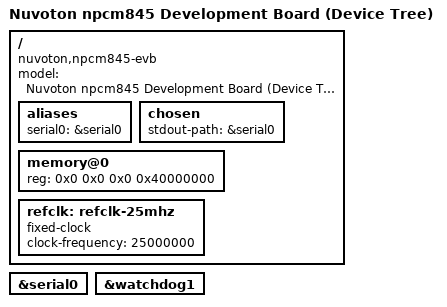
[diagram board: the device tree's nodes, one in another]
// SPDX-License-Identifier: GPL-2.0
// Copyright (c) 2021 Nuvoton Technology tomer.maimon@nuvoton.com

/dts-v1/;
#include "nuvoton-npcm845.dtsi"

/ {
	compatible = "nuvoton,npcm845-evb", "nuvoton,npcm845";
	model = "Nuvoton npcm845 Development Board (Device Tree)";

	aliases {
		serial0 = &serial0;
	};

	chosen {
		stdout-path = &serial0;
	};

	memory@0 {
		device_type = "memory";
		reg = <0x0 0x0 0x0 0x40000000>;
	};

	refclk: refclk-25mhz {
		compatible = "fixed-clock";
		#clock-cells = <0>;
		clock-frequency = <25000000>;
	};
};

&serial0 {
	status = "okay";
};

&watchdog1 {
	status = "okay";
};
